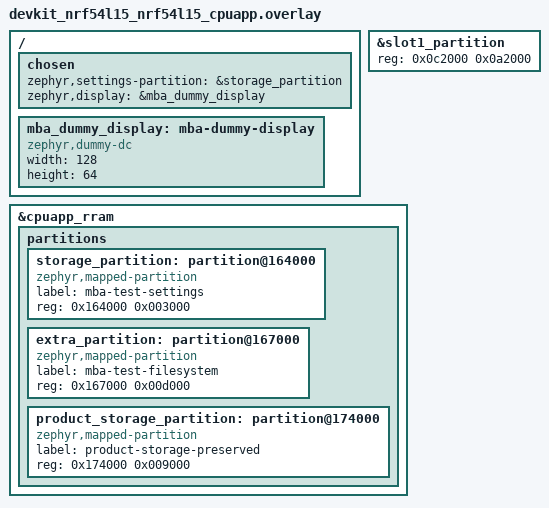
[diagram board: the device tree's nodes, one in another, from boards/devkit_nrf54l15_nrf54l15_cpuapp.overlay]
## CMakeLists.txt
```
# SPDX-FileCopyrightText: FoBE Studio
# SPDX-License-Identifier: Apache-2.0
cmake_minimum_required(VERSION 3.20.0)
find_package(Zephyr REQUIRED HINTS $ENV{ZEPHYR_BASE})
project(mbs_desktop_mba_service_dut)
include(${CMAKE_CURRENT_LIST_DIR}/../app.cmake)
target_sources(app PRIVATE src/storage.c)
```

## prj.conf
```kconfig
# SPDX-FileCopyrightText: FoBE Studio
# SPDX-License-Identifier: Apache-2.0

CONFIG_ZTEST=y
CONFIG_ASSERT=y
CONFIG_LOG=y
CONFIG_LOG_MODE_IMMEDIATE=y
CONFIG_USERSPACE=n
CONFIG_MPU=n
CONFIG_ARM_MPU=n
CONFIG_MBS=y
CONFIG_MBS_LLEXT=y
CONFIG_MBS_LLEXT_BRIDGE=n
CONFIG_MBS_LLEXT_DEFAULT_ENABLED=y
CONFIG_MBS_LLEXT_APP_HEAP_RESERVE_SIZE=32768
CONFIG_MBS_LLEXT_APP_MAX_HEAP_SIZE=32768
CONFIG_LLEXT=y
CONFIG_LLEXT_HEAP_DYNAMIC=y
CONFIG_DISPLAY=y
CONFIG_U8G2=y
CONFIG_ZUI=y
CONFIG_DYNAMIC_THREAD=y
CONFIG_THREAD_STACK_INFO=y
CONFIG_FILE_SYSTEM=y
CONFIG_FILE_SYSTEM_LITTLEFS=y
CONFIG_FS_LITTLEFS_FMP_DEV=y
CONFIG_FLASH=y
CONFIG_FLASH_MAP=y
CONFIG_FLASH_PAGE_LAYOUT=y
CONFIG_SETTINGS=y
CONFIG_SETTINGS_ZMS=y
CONFIG_ZMS=y
CONFIG_JSON_LIBRARY=y
CONFIG_PSA_CRYPTO=y
CONFIG_PSA_WANT_ALG_SHA_256=y
CONFIG_HEAP_MEM_POOL_SIZE=98304
CONFIG_MAIN_STACK_SIZE=4096
CONFIG_SYSTEM_WORKQUEUE_STACK_SIZE=4096
CONFIG_ZTEST_STACK_SIZE=4096
```

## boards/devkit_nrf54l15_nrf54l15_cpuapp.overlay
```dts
/* Dedicated test storage; never select product storage. See README.rst. */
/delete-node/ &storage_partition;

&slot1_partition {
	reg = <0x0c2000 0x0a2000>;
};

&cpuapp_rram {
	partitions {
		storage_partition: partition@164000 {
			compatible = "zephyr,mapped-partition";
			label = "mba-test-settings";
			reg = <0x164000 0x003000>;
		};
		extra_partition: partition@167000 {
			compatible = "zephyr,mapped-partition";
			label = "mba-test-filesystem";
			reg = <0x167000 0x00d000>;
		};
		product_storage_partition: partition@174000 {
			compatible = "zephyr,mapped-partition";
			label = "product-storage-preserved";
			reg = <0x174000 0x009000>;
		};
	};
};

/ {
	chosen {
		zephyr,settings-partition = &storage_partition;
		zephyr,display = &mba_dummy_display;
	};
	mba_dummy_display: mba-dummy-display {
		compatible = "zephyr,dummy-dc";
		width = <128>;
		height = <64>;
	};
};
```

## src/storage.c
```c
/* SPDX-FileCopyrightText: FoBE Studio */
/* SPDX-License-Identifier: Apache-2.0 */

#include <zephyr/init.h>
#include <zephyr/storage/flash_map.h>
#include <zephyr/sys/util.h>

#define SETTINGS DT_NODELABEL(storage_partition)
#define FILESYSTEM DT_NODELABEL(extra_partition)
#define PRODUCT DT_NODELABEL(product_storage_partition)
#define END(node) (DT_REG_ADDR(node) + DT_REG_SIZE(node))

BUILD_ASSERT(!IS_ENABLED(CONFIG_FLASH_SIMULATOR), "real RRAM is required");
BUILD_ASSERT(DT_REG_ADDR(SETTINGS) == 0x164000 && DT_REG_SIZE(SETTINGS) == 0x3000);
BUILD_ASSERT(DT_REG_ADDR(FILESYSTEM) == 0x167000 && DT_REG_SIZE(FILESYSTEM) == 0xd000);
BUILD_ASSERT(DT_REG_ADDR(PRODUCT) == 0x174000 && DT_REG_SIZE(PRODUCT) == 0x9000);
BUILD_ASSERT(END(DT_NODELABEL(slot0_partition)) <= DT_REG_ADDR(DT_NODELABEL(slot1_partition)));
BUILD_ASSERT(END(DT_NODELABEL(slot1_partition)) <= DT_REG_ADDR(SETTINGS));
BUILD_ASSERT(END(SETTINGS) <= DT_REG_ADDR(FILESYSTEM));
BUILD_ASSERT(END(FILESYSTEM) <= DT_REG_ADDR(PRODUCT));
BUILD_ASSERT(END(PRODUCT) <= DT_REG_SIZE(DT_MEM_FROM_PARTITION(PRODUCT)));

int mba_test_storage_prepare_rc;

static int flatten(int id)
{
	const struct flash_area *area;
	int ret = flash_area_open(id, &area);

	if (ret == 0) {
		ret = flash_area_flatten(area, 0, area->fa_size);
		flash_area_close(area);
	}
	return ret;
}

int mba_test_storage_cleanup(void)
{
	int ret = flatten(DT_PARTITION_ID(FILESYSTEM));

	if (ret == 0) {
		ret = flatten(DT_PARTITION_ID(SETTINGS));
	}
	return ret;
}

static int prepare(void)
{
	mba_test_storage_prepare_rc = mba_test_storage_cleanup();
	return mba_test_storage_prepare_rc;
}
SYS_INIT(prepare, POST_KERNEL, 98);
```
